# AT91SAM9M11 register map
Vendor: Atmel; Series: SAM9M; File version: 20130207
Registers are 32-bit, read-write, reset 0x0 unless marked. A register's access mark holds for its fields unless they carry their own. Offsets are from the block's base; [hi:lo] are bit positions; {n}, {i} and the like mark numbered series.

## TSADCC — Touch Screen ADC Controller
Base 0xFFFB0000; register names take the prefix TSADCC_
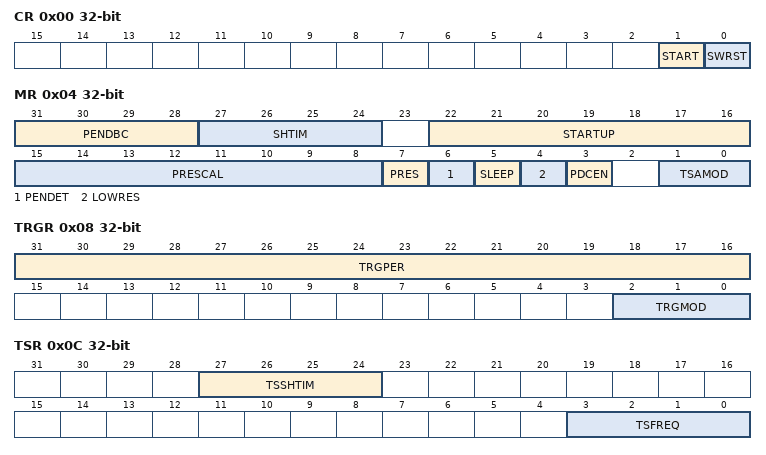
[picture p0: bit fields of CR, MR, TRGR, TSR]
0x00 CR wo reset not defined — Control Register
  [1] START — Start Conversion
  [0] SWRST — Software Reset
0x04 MR — Mode Register
  [31:28] PENDBC — Pen Detect debouncing period
  [27:24] SHTIM — Sample & Hold Time for ADC Channels
  [22:16] STARTUP — Start Up Time
  [15:8] PRESCAL — Prescaler Rate Selection
  [7] PRES — Pressure Measurement Selection
  [6] PENDET — Pen Detect Selection
  [5] SLEEP — Sleep Mode
  [4] LOWRES — Resolution Selection
  [3] PDCEN — PDC transfer in Touchscreen/Interleaved mode or Manual mode
  [1:0] TSAMOD — Touch Screen ADC Mode
0x08 TRGR — Trigger Register
  [31:16] TRGPER — Trigger Period
  [2:0] TRGMOD — Trigger Mode
0x0C TSR — Touch Screen Register
  [27:24] TSSHTIM — Sample & Hold Time for Touch Screen Channels
  [3:0] TSFREQ — Touch Screen Frequency in Interleaved Mode
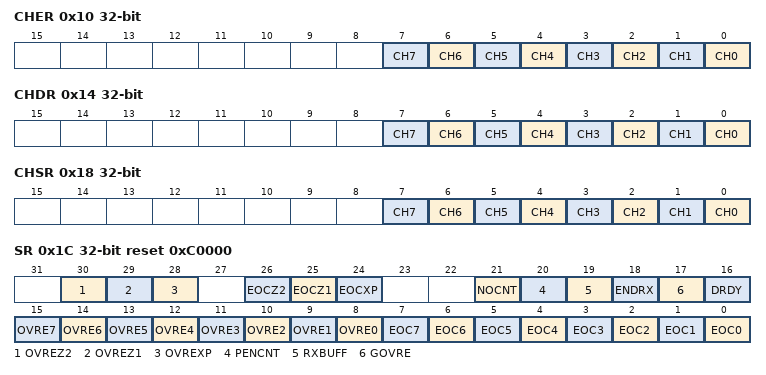
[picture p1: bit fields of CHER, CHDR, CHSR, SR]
0x10 CHER wo reset not defined — Channel Enable Register
  [n] CH{n} (n=0..7) — Channel {n} Enable
0x14 CHDR wo reset not defined — Channel Disable Register
  [n] CH{n} (n=0..7) — Channel {n} Disable
0x18 CHSR ro — Channel Status Register
  [n] CH{n} (n=0..7) — Channel {n} Status
0x1C SR ro reset 0xC0000 — Status Register
  [30] OVREZ2 — Overrun Error on Z2 Measure
  [29] OVREZ1 — Overrun Error on Z1 Measure
  [28] OVREXP — Overrun Error on X Position
  [26] EOCZ2 — End of Conversion Z2 Measure
  [25] EOCZ1 — End of Conversion Z1 Measure
  [24] EOCXP
  [21] NOCNT — No Contact
  [20] PENCNT — Pen Contact
  [19] RXBUFF — RX Buffer Full
  [18] ENDRX — End of RX Buffer
  [17] GOVRE — General Overrun Error
  [16] DRDY — Data Ready
  [n+8] OVRE{n} (n=0..7) — Overrun Error {n}
  [n] EOC{n} (n=0..7) — End of Conversion {n}
0x20 LCDR ro — Last Converted Data Register
  [9:0] LDATA — Last Data Converted
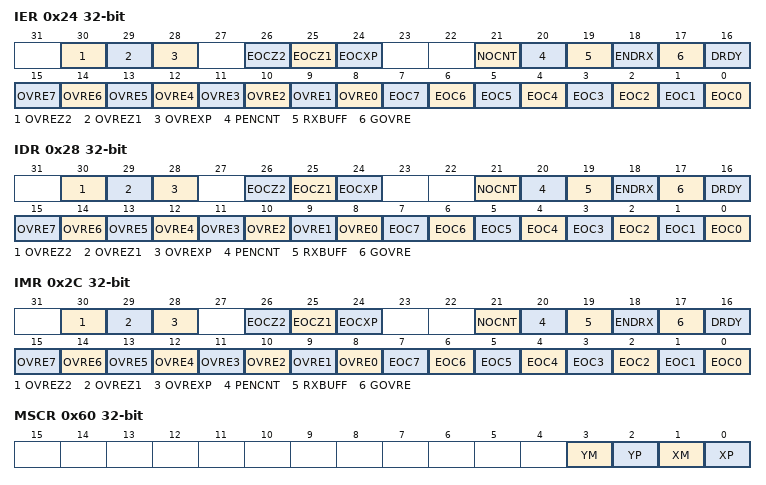
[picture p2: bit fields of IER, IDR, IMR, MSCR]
0x24 IER wo reset not defined — Interrupt Enable Register
  [30] OVREZ2 — Overrun Error Interrupt Enable Z2 Measure
  [29] OVREZ1 — Overrun Error Interrupt Enable Z1 Measure
  [28] OVREXP — Overrun Error Interrupt Enable X Position
  [26] EOCZ2 — End of Conversion Z2 Measure
  [25] EOCZ1 — End of Conversion Z1 Measure
  [24] EOCXP
  [21] NOCNT — No Contact
  [20] PENCNT — Pen Contact
  [19] RXBUFF — Receive Buffer Full Interrupt Enable
  [18] ENDRX — End of Receive Buffer Interrupt Enable
  [17] GOVRE — General Overrun Error Interrupt Enable
  [16] DRDY — Data Ready Interrupt Enable
  [n+8] OVRE{n} (n=0..7) — Overrun Error Interrupt Enable {n}
  [n] EOC{n} (n=0..7) — End of Conversion Interrupt Enable {n}
0x28 IDR wo reset not defined — Interrupt Disable Register
  [30] OVREZ2 — Overrun Error Interrupt Disable Z2 Measure
  [29] OVREZ1 — Overrun Error Interrupt Disable Z1 Measure
  [28] OVREXP — Overrun Error Interrupt Disable X Position
  [26] EOCZ2 — End of Conversion Z2 Measure
  [25] EOCZ1 — End of Conversion Z1 Measure
  [24] EOCXP
  [21] NOCNT — No Contact
  [20] PENCNT — Pen Contact
  [19] RXBUFF — Receive Buffer Full Interrupt Disable
  [18] ENDRX — End of Receive Buffer Interrupt Disable
  [17] GOVRE — General Overrun Error Interrupt Disable
  [16] DRDY — Data Ready Interrupt Disable
  [n+8] OVRE{n} (n=0..7) — Overrun Error Interrupt Disable {n}
  [n] EOC{n} (n=0..7) — End of Conversion Interrupt Disable {n}
0x2C IMR ro — Interrupt Mask Register
  [30] OVREZ2 — Overrun Error Interrupt Mask Z2 Measure
  [29] OVREZ1 — Overrun Error Interrupt Mask Z1 Measure
  [28] OVREXP — Overrun Error Interrupt Mask X Position
  [26] EOCZ2 — End of Conversion Z2 Measure
  [25] EOCZ1 — End of Conversion Z1 Measure
  [24] EOCXP
  [21] NOCNT — No Contact
  [20] PENCNT — Pen Contact
  [19] RXBUFF — Receive Buffer Full Interrupt Mask
  [18] ENDRX — End of Receive Buffer Interrupt Mask
  [17] GOVRE — General Overrun Error Interrupt Mask
  [16] DRDY — Data Ready Interrupt Mask
  [n+8] OVRE{n} (n=0..7) — Overrun Error Interrupt Mask {n}
  [n] EOC{n} (n=0..7) — End of Conversion Interrupt Mask {n}
{0x30+4i} CDR[{i}] (i=0..7) ro reset not defined — Channel Data Register
  [9:0] DATA — Channel Data
0x50 XPDR ro — X Position Data Register
  [9:0] DATA — X Position Data
0x54 Z1DR ro — Z1 Data Register
  [9:0] DATA — Z1 Measurement Data
0x58 Z2DR ro — Z2 Data Register
  [9:0] Z2 — Z2 Measurement Data
0x60 MSCR reset not defined — Manual Switch Command Register
  [3] YM — Switch Command
  [2] YP — Switch Command
  [1] XM — Switch Command
  [0] XP — Switch Command
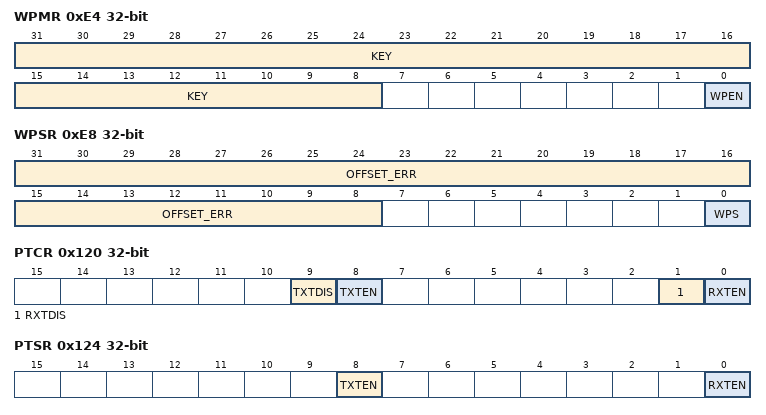
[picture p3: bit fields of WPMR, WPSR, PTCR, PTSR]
0xE4 WPMR reset not defined — Write Protection Mode Register
  [31:8] KEY
  [0] WPEN — Write Protection of TSADCC_MR, TSADCC_TRGR and TSADCC_TSR
0xE8 WPSR wo reset not defined — Write Protection Status Register
  [31:8] OFFSET_ERR — Offset error
  [0] WPS — Write Protection Status
0x100 RPR — Receive Pointer Register
  [31:0] RXPTR
0x104 RCR — Receive Counter Register
  [15:0] RXCTR
0x110 RNPR — Receive Next Pointer Register
  [31:0] RXNPTR — Receive Next Pointer
0x114 RNCR — Receive Next Counter Register
  [15:0] RXNCTR — Receive Next Counter
0x120 PTCR wo — Transfer Control Register
  [9] TXTDIS — Transmitter Transfer Disable
  [8] TXTEN — Transmitter Transfer Enable
  [1] RXTDIS — Receiver Transfer Disable
  [0] RXTEN — Receiver Transfer Enable
0x124 PTSR ro — Transfer Status Register
  [8] TXTEN — Transmitter Transfer Enable
  [0] RXTEN — Receiver Transfer Enable
